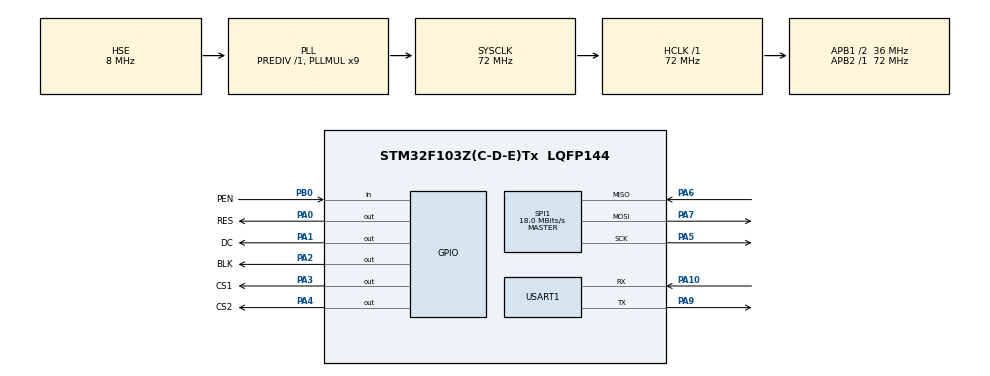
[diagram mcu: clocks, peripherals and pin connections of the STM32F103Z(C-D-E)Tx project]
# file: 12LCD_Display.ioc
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Mcu.Family=STM32F1
Mcu.Name=STM32F103Z(C-D-E)Tx
Mcu.Package=LQFP144
NVIC.PriorityGroup=NVIC_PRIORITYGROUP_4
OSC_IN.Mode=HSE-External-Oscillator
OSC_IN.Signal=RCC_OSC_IN
OSC_OUT.Mode=HSE-External-Oscillator
OSC_OUT.Signal=RCC_OSC_OUT
PA0-WKUP.GPIO_Label=RES
PA0-WKUP.GPIO_PuPd=GPIO_PULLUP
PA0-WKUP.PinState=GPIO_PIN_SET
PA0-WKUP.Signal=GPIO_Output
PA1.GPIO_Label=DC
PA1.GPIO_PuPd=GPIO_PULLUP
PA1.PinState=GPIO_PIN_SET
PA1.Signal=GPIO_Output
PA10.Mode=Asynchronous
PA10.Signal=USART1_RX
PA13.Mode=Serial_Wire
PA13.Signal=SYS_JTMS-SWDIO
PA14.Mode=Serial_Wire
PA14.Signal=SYS_JTCK-SWCLK
PA2.GPIO_Label=BLK
PA2.GPIO_PuPd=GPIO_PULLUP
PA2.PinState=GPIO_PIN_SET
PA2.Signal=GPIO_Output
PA3.GPIO_Label=CS1
PA3.GPIO_PuPd=GPIO_PULLUP
PA3.PinState=GPIO_PIN_SET
PA3.Signal=GPIO_Output
PA4.GPIO_Label=CS2
PA4.GPIO_PuPd=GPIO_PULLUP
PA4.PinState=GPIO_PIN_SET
PA4.Signal=GPIO_Output
PA5.Mode=Full_Duplex_Master
PA5.Signal=SPI1_SCK
PA6.Mode=Full_Duplex_Master
PA6.Signal=SPI1_MISO
PA7.Mode=Full_Duplex_Master
PA7.Signal=SPI1_MOSI
PA9.Mode=Asynchronous
PA9.Signal=USART1_TX
PB0.GPIO_Label=PEN
PB0.GPIO_PuPd=GPIO_PULLUP
PB0.Signal=GPIO_Input
ProjectManager.HeapSize=0x200
ProjectManager.StackSize=0x400
ProjectManager.TargetToolchain=MDK-ARM V5.32
RCC.AHBFreq_Value=72000000
RCC.APB1CLKDivider=RCC_HCLK_DIV2
RCC.APB1Freq_Value=36000000
RCC.APB1TimFreq_Value=72000000
RCC.APB2Freq_Value=72000000
RCC.APB2TimFreq_Value=72000000
RCC.HCLKFreq_Value=72000000
RCC.PLLMUL=RCC_PLL_MUL9
RCC.PLLSourceVirtual=RCC_PLLSOURCE_HSE
RCC.SYSCLKFreq_VALUE=72000000
RCC.SYSCLKSource=RCC_SYSCLKSOURCE_PLLCLK
RCC.USBFreq_Value=72000000
SPI1.BaudRatePrescaler=SPI_BAUDRATEPRESCALER_4
SPI1.CalculateBaudRate=18.0 MBits/s
SPI1.Direction=SPI_DIRECTION_2LINES
SPI1.Mode=SPI_MODE_MASTER
SPI1.VirtualType=VM_MASTER
USART1.VirtualMode=VM_ASYNC
board=custom

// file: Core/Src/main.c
/* USER CODE BEGIN Header */
/**
  ******************************************************************************
  * @file           : main.c
  * @brief          : Main program body
  ******************************************************************************
  * @attention
  *
  * Copyright (c) 2024 STMicroelectronics.
  * All rights reserved.
  *
  * This software is licensed under terms that can be found in the LICENSE file
  * in the root directory of this software component.
  * If no LICENSE file comes with this software, it is provided AS-IS.
  *
  ******************************************************************************
  */
/* USER CODE END Header */
#include "main.h"
#include "spi.h"
#include "usart.h"
#include "gpio.h"

/* USER CODE BEGIN Includes */
#include "lcd_init.h"
#include "lcd.h"
#include "pic.h"
/* USER CODE END Includes */

void SystemClock_Config(void);

int main(void)
{

  /* USER CODE BEGIN 1 */
	u8 i,j;
	float t=0;
  /* USER CODE END 1 */

  /* MCU Configuration--------------------------------------------------------*/

  /* Reset of all peripherals, Initializes the Flash interface and the Systick. */
  HAL_Init();

  /* Configure the system clock */
  SystemClock_Config();

  /* Initialize all configured peripherals */
  MX_GPIO_Init();
  MX_SPI1_Init();
  MX_USART1_UART_Init();
  /* USER CODE BEGIN 2 */
	LCD_Init();//LCD初始化
//	LCD_Fill(0,0,LCD_W,LCD_H,GRED);

	LCD_ShowPicture(0,0,300,392,gImage_bmp4);
//	HAL_Delay(1000);
//	LCD_Fill(0,0,LCD_W,LCD_H,WHITE);
//	LCD_ShowChinese(0,0,"中景园电子",RED,WHITE,32,0);
//	LCD_ShowString(0,40,"LCD_W:",RED,WHITE,16,0);
//	LCD_ShowIntNum(48,40,LCD_W,3,RED,WHITE,16);
//	LCD_ShowString(80,40,"LCD_H:",RED,WHITE,16,0);
//	LCD_ShowIntNum(128,40,LCD_H,3,RED,WHITE,16);
//	LCD_ShowString(80,40,"LCD_H:",RED,WHITE,16,0);
//	LCD_ShowString(0,70,"Increaseing Nun:",RED,WHITE,16,0);
//	LCD_ShowFloatNum1(128,70,t,4,RED,WHITE,16);
//	t+=0.11;
//	for(j=0;j<7;j++)
//	{
//		for(i=0;i<8;i++)
//		{
//			LCD_ShowPicture(40*i,200+j*40,40,40,gImage_1);
//		}
//	}
  /* USER CODE END 2 */

  /* Infinite loop */
  while (1)
  {

  }
}

void SystemClock_Config(void)
{
  RCC_OscInitTypeDef RCC_OscInitStruct = {0};
  RCC_ClkInitTypeDef RCC_ClkInitStruct = {0};

  /** Initializes the RCC Oscillators according to the specified parameters
  * in the RCC_OscInitTypeDef structure.
  */
  RCC_OscInitStruct.OscillatorType = RCC_OSCILLATORTYPE_HSE;
  RCC_OscInitStruct.HSEState = RCC_HSE_ON;
  RCC_OscInitStruct.HSEPredivValue = RCC_HSE_PREDIV_DIV1;
  RCC_OscInitStruct.HSIState = RCC_HSI_ON;
  RCC_OscInitStruct.PLL.PLLState = RCC_PLL_ON;
  RCC_OscInitStruct.PLL.PLLSource = RCC_PLLSOURCE_HSE;
  RCC_OscInitStruct.PLL.PLLMUL = RCC_PLL_MUL9;
  if (HAL_RCC_OscConfig(&RCC_OscInitStruct) != HAL_OK)
  {
    Error_Handler();
  }

  /** Initializes the CPU, AHB and APB buses clocks
  */
  RCC_ClkInitStruct.ClockType = RCC_CLOCKTYPE_HCLK|RCC_CLOCKTYPE_SYSCLK
                              |RCC_CLOCKTYPE_PCLK1|RCC_CLOCKTYPE_PCLK2;
  RCC_ClkInitStruct.SYSCLKSource = RCC_SYSCLKSOURCE_PLLCLK;
  RCC_ClkInitStruct.AHBCLKDivider = RCC_SYSCLK_DIV1;
  RCC_ClkInitStruct.APB1CLKDivider = RCC_HCLK_DIV2;
  RCC_ClkInitStruct.APB2CLKDivider = RCC_HCLK_DIV1;

  if (HAL_RCC_ClockConfig(&RCC_ClkInitStruct, FLASH_LATENCY_2) != HAL_OK)
  {
    Error_Handler();
  }
}

void Error_Handler(void)
{
  __disable_irq();
  while (1)
  {
  }
}
